AUTOSAR XML (schema 00044)
package /VAG/Services/BAP
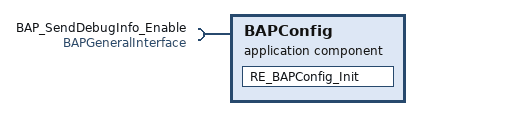
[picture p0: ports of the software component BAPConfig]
  application sw component type BAPConfig
    require port BAP_SendDebugInfo_Enable: client-com-spec=BAP_SendDebugInfo_Enable, required-interface=BAPGeneralInterface
    behavior IB_BAPConfig
      init event RE_BAPConfig_InitEvent: start-on-event=RE_BAPConfig_Init
      runnable RE_BAPConfig_Init: can-be-invoked-concurrently=true, symbol=BAP_ASR_BAPConfig_Init
        sync call SCP_BAP_SendDebugInfo_Enable_BAP_SendDebugInfo_Enable: operation=BAP_SendDebugInfo_Enable.BAP_SendDebugInfo_Enable
  swc implementation Impl_BAPConfig: behavior=IB_BAPConfig
    code-descriptors:
      code Code
